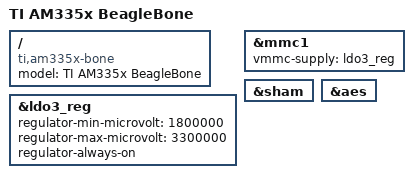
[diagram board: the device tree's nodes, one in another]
/*
 * Copyright (C) 2012 Texas Instruments Incorporated - http://www.ti.com/
 *
 * This program is free software; you can redistribute it and/or modify
 * it under the terms of the GNU General Public License version 2 as
 * published by the Free Software Foundation.
 */
/dts-v1/;

#include "am33xx.dtsi"
#include "am335x-bone-common.dtsi"

/ {
	model = "TI AM335x BeagleBone";
	compatible = "ti,am335x-bone", "ti,am33xx";
};

&ldo3_reg {
	regulator-min-microvolt = <1800000>;
	regulator-max-microvolt = <3300000>;
	regulator-always-on;
};

&mmc1 {
	vmmc-supply = <&ldo3_reg>;
};

&sham {
	status = "okay";
};

&aes {
	status = "okay";
};
